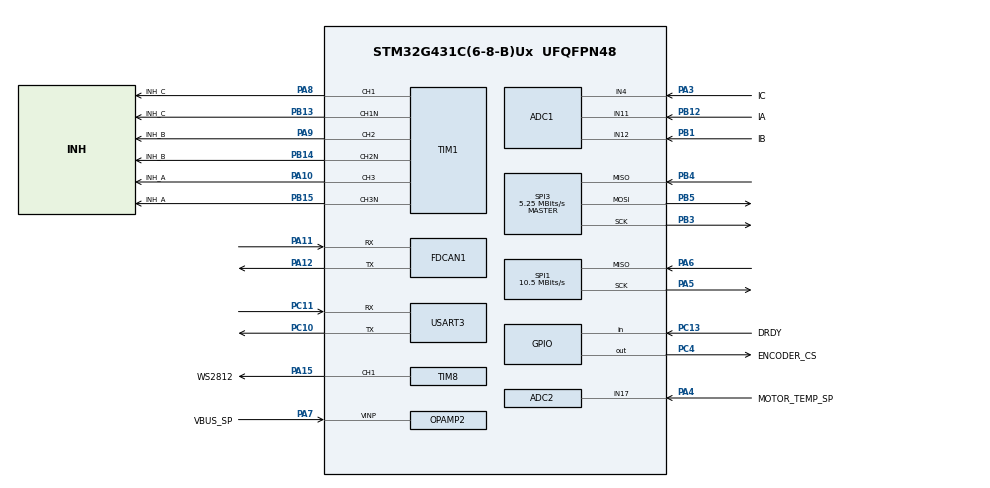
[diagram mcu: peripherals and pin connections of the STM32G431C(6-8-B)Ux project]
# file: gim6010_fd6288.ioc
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ADC1.EnableInjectedConversion=ENABLE
ADC1.EnableRegularConversion=DISABLE
ADC1.ExternalTrigInjecConv=ADC_EXTERNALTRIGINJEC_T1_CC4
ADC1.InjNumberOfConversion=3
ADC1.InjectedChannel-2\#ChannelInjectedConversion=ADC_CHANNEL_11
ADC1.InjectedChannel-3\#ChannelInjectedConversion=ADC_CHANNEL_12
ADC1.InjectedChannel-4\#ChannelInjectedConversion=ADC_CHANNEL_4
ADC1.InjectedOffsetNumber-2\#ChannelInjectedConversion=ADC_OFFSET_NONE
ADC1.InjectedOffsetNumber-3\#ChannelInjectedConversion=ADC_OFFSET_NONE
ADC1.InjectedOffsetNumber-4\#ChannelInjectedConversion=ADC_OFFSET_NONE
ADC1.InjectedRank-2\#ChannelInjectedConversion=1
ADC1.InjectedRank-3\#ChannelInjectedConversion=2
ADC1.InjectedRank-4\#ChannelInjectedConversion=3
ADC1.InjectedSamplingTime-2\#ChannelInjectedConversion=ADC_SAMPLETIME_12CYCLES_5
ADC1.InjectedSamplingTime-3\#ChannelInjectedConversion=ADC_SAMPLETIME_12CYCLES_5
ADC1.InjectedSamplingTime-4\#ChannelInjectedConversion=ADC_SAMPLETIME_12CYCLES_5
ADC1.Rank1_Channel=ADC_CHANNEL_11
ADC1.Rank2_Channel=ADC_CHANNEL_12
ADC1.Rank3_Channel=ADC_CHANNEL_4
ADC1.master=1
ADC2.ContinuousConvMode=DISABLE
ADC2.DMAContinuousRequests=DISABLE
ADC2.EnableInjectedConversion=ENABLE
ADC2.EnableRegularConversion=DISABLE
ADC2.ExternalTrigInjecConv=ADC_EXTERNALTRIGINJEC_T1_CC4
ADC2.InjNumberOfConversion=2
ADC2.InjectedChannel-5\#ChannelInjectedConversion=ADC_CHANNEL_VOPAMP2
ADC2.InjectedChannel-6\#ChannelInjectedConversion=ADC_CHANNEL_17
ADC2.InjectedOffsetNumber-5\#ChannelInjectedConversion=ADC_OFFSET_NONE
ADC2.InjectedOffsetNumber-6\#ChannelInjectedConversion=ADC_OFFSET_NONE
ADC2.InjectedRank-5\#ChannelInjectedConversion=1
ADC2.InjectedRank-6\#ChannelInjectedConversion=2
ADC2.InjectedSamplingTime-5\#ChannelInjectedConversion=ADC_SAMPLETIME_6CYCLES_5
ADC2.InjectedSamplingTime-6\#ChannelInjectedConversion=ADC_SAMPLETIME_6CYCLES_5
ADC2.OversamplingMode=DISABLE
ADC2.Rank1_Channel=ADC_CHANNEL_VOPAMP2
ADC2.Rank2_Channel=ADC_CHANNEL_17
Dma.Request0=TIM8_CH1
Dma.Request1=SPI1_RX
Dma.SPI1_RX.1.Direction=DMA_PERIPH_TO_MEMORY
Dma.SPI1_RX.1.EventEnable=DISABLE
Dma.SPI1_RX.1.Instance=DMA1_Channel1
Dma.SPI1_RX.1.MemDataAlignment=DMA_MDATAALIGN_BYTE
Dma.SPI1_RX.1.MemInc=DMA_MINC_ENABLE
Dma.SPI1_RX.1.Mode=DMA_NORMAL
Dma.SPI1_RX.1.PeriphDataAlignment=DMA_PDATAALIGN_BYTE
Dma.SPI1_RX.1.PeriphInc=DMA_PINC_DISABLE
Dma.SPI1_RX.1.Polarity=HAL_DMAMUX_REQ_GEN_RISING
Dma.SPI1_RX.1.Priority=DMA_PRIORITY_VERY_HIGH
Dma.SPI1_RX.1.RequestNumber=1
Dma.SPI1_RX.1.SignalID=NONE
Dma.SPI1_RX.1.SyncEnable=DISABLE
Dma.SPI1_RX.1.SyncPolarity=HAL_DMAMUX_SYNC_NO_EVENT
Dma.SPI1_RX.1.SyncRequestNumber=1
Dma.SPI1_RX.1.SyncSignalID=NONE
Dma.TIM8_CH1.0.Direction=DMA_MEMORY_TO_PERIPH
Dma.TIM8_CH1.0.EventEnable=DISABLE
Dma.TIM8_CH1.0.Instance=DMA2_Channel1
Dma.TIM8_CH1.0.MemDataAlignment=DMA_MDATAALIGN_HALFWORD
Dma.TIM8_CH1.0.MemInc=DMA_MINC_ENABLE
Dma.TIM8_CH1.0.Mode=DMA_CIRCULAR
Dma.TIM8_CH1.0.PeriphDataAlignment=DMA_PDATAALIGN_HALFWORD
Dma.TIM8_CH1.0.PeriphInc=DMA_PINC_DISABLE
Dma.TIM8_CH1.0.Polarity=HAL_DMAMUX_REQ_GEN_RISING
Dma.TIM8_CH1.0.Priority=DMA_PRIORITY_LOW
Dma.TIM8_CH1.0.RequestNumber=1
Dma.TIM8_CH1.0.SignalID=NONE
Dma.TIM8_CH1.0.SyncEnable=DISABLE
Dma.TIM8_CH1.0.SyncPolarity=HAL_DMAMUX_SYNC_NO_EVENT
Dma.TIM8_CH1.0.SyncRequestNumber=1
Dma.TIM8_CH1.0.SyncSignalID=NONE
FDCAN1.AutoRetransmission=DISABLE
FDCAN1.CalculateBaudRateNominal=1000000
FDCAN1.CalculateTimeBitNominal=1000
FDCAN1.CalculateTimeQuantumNominal=35.714285714285715
FDCAN1.DataPrescaler=6
FDCAN1.DataSyncJumpWidth=7
FDCAN1.DataTimeSeg1=20
FDCAN1.DataTimeSeg2=7
FDCAN1.ExtFiltersNbr=0
FDCAN1.NominalPrescaler=6
FDCAN1.NominalSyncJumpWidth=7
FDCAN1.NominalTimeSeg1=20
FDCAN1.NominalTimeSeg2=7
FDCAN1.StdFiltersNbr=1
Mcu.Family=STM32G4
Mcu.Name=STM32G431C(6-8-B)Ux
Mcu.Package=UFQFPN48
Mcu.UserConstants=PWM_TGRO_TIME,PWM_PERIOD_CLOCKS-10;PWM_DEADTIM_CLOCKS,34;PWM_RCR,0;PWM_PERIOD_CLOCKS,PWM_CLOCK_HZ/2/PWM_FREQ;PWM_FREQ,24000;PWM_CLOCK_HZ,168000000
NVIC.ADC1_2_IRQn=true\:0\:0\:true\:false\:true\:true\:true\:true
NVIC.DMA1_Channel1_IRQn=true\:0\:0\:false\:false\:true\:false\:true\:true
NVIC.DMA2_Channel1_IRQn=true\:0\:0\:false\:false\:true\:false\:true\:true
NVIC.FDCAN1_IT0_IRQn=true\:0\:0\:false\:false\:true\:true\:true\:true
NVIC.PriorityGroup=NVIC_PRIORITYGROUP_4
NVIC.TIM1_UP_TIM16_IRQn=true\:0\:0\:false\:false\:true\:true\:true\:true
NVIC.TIM4_IRQn=true\:0\:0\:false\:false\:true\:true\:true\:true
NVIC.TIM7_IRQn=true\:0\:0\:false\:false\:true\:true\:true\:true
OPAMP2.PowerMode=OPAMP_POWERMODE_HIGHSPEED
PA10.GPIO_Label=INH_A
PA10.Signal=S_TIM1_CH3
PA11.Mode=FDCAN_Activate
PA11.Signal=FDCAN1_RX
PA12.Mode=FDCAN_Activate
PA12.Signal=FDCAN1_TX
PA13.Mode=Serial_Wire
PA13.Signal=SYS_JTMS-SWDIO
PA14.Mode=Serial_Wire
PA14.Signal=SYS_JTCK-SWCLK
PA15.GPIO_Label=WS2812
PA15.Signal=S_TIM8_CH1
PA3.GPIO_Label=IC
PA3.Mode=IN4-Single-Ended
PA3.Signal=ADC1_IN4
PA4.GPIO_Label=MOTOR_TEMP_SP
PA4.Mode=IN17-Single-Ended
PA4.Signal=ADC2_IN17
PA5.GPIO_PuPd=GPIO_PULLDOWN
PA5.GPIO_Speed=GPIO_SPEED_FREQ_VERY_HIGH
PA5.Mode=RX_Only_Simplex_Unidirect_Master
PA5.Signal=SPI1_SCK
PA6.GPIO_Mode=GPIO_MODE_AF_PP
PA6.GPIO_PuPd=GPIO_PULLDOWN
PA6.GPIO_Speed=GPIO_SPEED_FREQ_VERY_HIGH
PA6.Mode=RX_Only_Simplex_Unidirect_Master
PA6.Signal=SPI1_MISO
PA7.GPIO_Label=VBUS_SP
PA7.Mode=Follower_Internally_Connected
PA7.Signal=OPAMP2_VINP
PA8.GPIO_Label=INH_C
PA8.Signal=S_TIM1_CH1
PA9.GPIO_Label=INH_B
PA9.Signal=S_TIM1_CH2
PB1.GPIO_Label=IB
PB1.Mode=IN12-Single-Ended
PB1.Signal=ADC1_IN12
PB12.GPIO_Label=IA
PB12.Mode=IN11-Single-Ended
PB12.Signal=ADC1_IN11
PB13.GPIO_Label=INH_C
PB13.Mode=PWM Generation1 CH1 CH1N
PB13.Signal=TIM1_CH1N
PB14.GPIO_Label=INH_B
PB14.Mode=PWM Generation2 CH2 CH2N
PB14.Signal=TIM1_CH2N
PB15.GPIO_Label=INH_A
PB15.Mode=PWM Generation3 CH3 CH3N
PB15.Signal=TIM1_CH3N
PB3.GPIO_Speed=GPIO_SPEED_FREQ_VERY_HIGH
PB3.Mode=Full_Duplex_Master
PB3.Signal=SPI3_SCK
PB4.GPIO_Speed=GPIO_SPEED_FREQ_VERY_HIGH
PB4.Mode=Full_Duplex_Master
PB4.Signal=SPI3_MISO
PB5.GPIO_Speed=GPIO_SPEED_FREQ_VERY_HIGH
PB5.Mode=Full_Duplex_Master
PB5.Signal=SPI3_MOSI
PC10.Mode=Asynchronous
PC10.Signal=USART3_TX
PC11.Mode=Asynchronous
PC11.Signal=USART3_RX
PC13.GPIO_Label=DRDY
PC13.Signal=GPIO_Input
PC4.GPIO_Label=ENCODER_CS
PC4.GPIO_PuPd=GPIO_PULLUP
PC4.GPIO_Speed=GPIO_SPEED_FREQ_VERY_HIGH
PC4.PinState=GPIO_PIN_SET
PC4.Signal=GPIO_Output
PF0-OSC_IN.Mode=HSE-External-Oscillator
PF0-OSC_IN.Signal=RCC_OSC_IN
PF1-OSC_OUT.Mode=HSE-External-Oscillator
PF1-OSC_OUT.Signal=RCC_OSC_OUT
ProjectManager.HeapSize=0x200
ProjectManager.StackSize=0x400
ProjectManager.TargetToolchain=STM32CubeIDE
RCC.ADC12Freq_Value=168000000
RCC.AHBFreq_Value=168000000
RCC.APB1Freq_Value=168000000
RCC.APB1TimFreq_Value=168000000
RCC.APB2Freq_Value=168000000
RCC.APB2TimFreq_Value=168000000
RCC.CortexFreq_Value=168000000
RCC.EXTERNAL_CLOCK_VALUE=12288000
RCC.EnbaleCSS=true
RCC.HCLKFreq_Value=168000000
RCC.HSE_VALUE=24000000
RCC.HSI48_VALUE=48000000
RCC.HSI_VALUE=16000000
RCC.LPTIM1CLockSelection=RCC_LPTIM1CLKSOURCE_HSI
RCC.LSE_VALUE=32768
RCC.PLLM=RCC_PLLM_DIV2
RCC.PLLN=28
RCC.PLLSourceVirtual=RCC_PLLSOURCE_HSE
RCC.SYSCLKFreq_VALUE=168000000
RCC.SYSCLKSource=RCC_SYSCLKSOURCE_PLLCLK
RCC.USBFreq_Value=168000000
RCC.VCOOutputFreq_Value=336000000
SH.S_TIM1_CH1.0=TIM1_CH1,PWM Generation1 CH1 CH1N
SH.S_TIM1_CH2.0=TIM1_CH2,PWM Generation2 CH2 CH2N
SH.S_TIM1_CH3.0=TIM1_CH3,PWM Generation3 CH3 CH3N
SH.S_TIM8_CH1.0=TIM8_CH1,PWM Generation1 CH1
SPI1.BaudRatePrescaler=SPI_BAUDRATEPRESCALER_16
SPI1.CLKPhase=SPI_PHASE_2EDGE
SPI1.CalculateBaudRate=10.5 MBits/s
SPI1.DataSize=SPI_DATASIZE_8BIT
SPI1.Direction=SPI_DIRECTION_2LINES_RXONLY
SPI1.Mode=SPI_MODE_MASTER
SPI1.VirtualType=VM_MASTER
SPI3.BaudRatePrescaler=SPI_BAUDRATEPRESCALER_32
SPI3.CalculateBaudRate=5.25 MBits/s
SPI3.DataSize=SPI_DATASIZE_8BIT
SPI3.Direction=SPI_DIRECTION_2LINES
SPI3.FirstBit=SPI_FIRSTBIT_MSB
SPI3.Mode=SPI_MODE_MASTER
SPI3.NSSPMode=SPI_NSS_PULSE_DISABLE
SPI3.VirtualType=VM_MASTER
STMicroelectronics.X-CUBE-ALGOBUILD.1.4.0.LibraryCcDSPOoLibraryJjDSPOoLibrary=true
TIM1.AutoReloadPreload=TIM_AUTORELOAD_PRELOAD_DISABLE
TIM1.Channel-PWM\ Generation1\ CH1\ CH1N=TIM_CHANNEL_1
TIM1.Channel-PWM\ Generation2\ CH2\ CH2N=TIM_CHANNEL_2
TIM1.Channel-PWM\ Generation3\ CH3\ CH3N=TIM_CHANNEL_3
TIM1.Channel-PWM\ Generation4\ No\ Output=TIM_CHANNEL_4
TIM1.CounterMode=TIM_COUNTERMODE_CENTERALIGNED1
TIM1.DeadTime=PWM_DEADTIM_CLOCKS
TIM1.OCFastMode_PWM-PWM\ Generation1\ CH1\ CH1N=TIM_OCFAST_DISABLE
TIM1.OCFastMode_PWM-PWM\ Generation2\ CH2\ CH2N=TIM_OCFAST_DISABLE
TIM1.OCFastMode_PWM-PWM\ Generation3\ CH3\ CH3N=TIM_OCFAST_DISABLE
TIM1.OCMode_PWM-PWM\ Generation1\ CH1\ CH1N=TIM_OCMODE_PWM1
TIM1.OCMode_PWM-PWM\ Generation2\ CH2\ CH2N=TIM_OCMODE_PWM1
TIM1.OCMode_PWM-PWM\ Generation3\ CH3\ CH3N=TIM_OCMODE_PWM1
TIM1.OCMode_PWM-PWM\ Generation4\ No\ Output=TIM_OCMODE_PWM2
TIM1.OCPolarity_4=TIM_OCPOLARITY_HIGH
TIM1.OffStateIDLEMode=TIM_OSSI_DISABLE
TIM1.OffStateRunMode=TIM_OSSR_DISABLE
TIM1.PeriodNoDither=PWM_PERIOD_CLOCKS
TIM1.PulseNoDither_1=0
TIM1.PulseNoDither_2=0
TIM1.PulseNoDither_3=0
TIM1.PulseNoDither_4=PWM_TGRO_TIME
TIM1.RepetitionCounter=PWM_RCR
TIM1.TIM_MasterOutputTrigger=TIM_TRGO_OC4REF
TIM4.PeriodNoDither=1000-1
TIM4.Prescaler=170-1
TIM7.PeriodNoDither=5000-1
TIM7.Prescaler=170-1
TIM8.AutoReloadPreload=TIM_AUTORELOAD_PRELOAD_ENABLE
TIM8.Channel-PWM\ Generation1\ CH1=TIM_CHANNEL_1
TIM8.PeriodNoDither=60-1
TIM8.Prescaler=4-1
USART3.VirtualMode-Asynchronous=VM_ASYNC
VP_ADC2_OPAMP_INTERNAL2.Mode=IN-OPAMP2
VP_STMicroelectronics.X-CUBE-ALGOBUILD_VS_DSPOoLibraryJjLibrary_1.4.0_1.4.0.Mode=DSPOoLibraryJjLibrary
VP_SYS_VS_DBSignals.Mode=DisableDeadBatterySignals
VP_TIM1_VS_ClockSourceINT.Mode=Internal
VP_TIM1_VS_no_output4.Mode=PWM Generation4 No Output
VP_TIM4_VS_ClockSourceINT.Mode=Internal
VP_TIM7_VS_ClockSourceINT.Mode=Enable_Timer
VP_TIM8_VS_ClockSourceINT.Mode=Internal
board=custom

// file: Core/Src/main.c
/* USER CODE BEGIN Header */
/**
 ******************************************************************************
 * @file           : main.c
 * @brief          : Main program body
 ******************************************************************************
 * @attention
 *
 * Copyright (c) 2025 STMicroelectronics.
 * All rights reserved.
 *
 * This software is licensed under terms that can be found in the LICENSE file
 * in the root directory of this software component.
 * If no LICENSE file comes with this software, it is provided AS-IS.
 *
 ******************************************************************************
 */
/* USER CODE END Header */
#include "main.h"
#include "adc.h"
#include "dma.h"
#include "fdcan.h"
#include "opamp.h"
#include "spi.h"
#include "tim.h"
#include "usart.h"
#include "gpio.h"

/* USER CODE BEGIN Includes */
#include "motor.h"
#include "ads1120.h"
#include <math.h>
#include <stdint.h>
/* USER CODE END Includes */

void SystemClock_Config(void);

int main(void)
{

    /* MCU Configuration--------------------------------------------------------*/

    /* Reset of all peripherals, Initializes the Flash interface and the Systick. */
    HAL_Init();

    /* Configure the system clock */
    SystemClock_Config();

    /* Initialize all configured peripherals */
    MX_GPIO_Init();
    MX_DMA_Init();
    MX_FDCAN1_Init();
    MX_TIM1_Init();
    MX_SPI1_Init();
    MX_SPI3_Init();
    MX_USART3_UART_Init();
    MX_ADC1_Init();
    MX_ADC2_Init();
    MX_OPAMP2_Init();
    MX_TIM4_Init();
    MX_TIM7_Init();
    MX_TIM8_Init();
    /* USER CODE BEGIN 2 */
    ADS1220Init();
    // MotorInit();
    /* USER CODE END 2 */

    /* Infinite loop */
    /* USER CODE BEGIN WHILE */
    static float angle;
    while (1) {
        angle = Hall_calc_angle();
        /* USER CODE END WHILE */

    }
}

void SystemClock_Config(void)
{
    LL_FLASH_SetLatency(LL_FLASH_LATENCY_4);
    while (LL_FLASH_GetLatency() != LL_FLASH_LATENCY_4) {
    }
    LL_PWR_EnableRange1BoostMode();
    LL_RCC_HSE_Enable();
    /* Wait till HSE is ready */
    while (LL_RCC_HSE_IsReady() != 1) {
    }

    LL_RCC_HSE_EnableCSS();
    LL_RCC_PLL_ConfigDomain_SYS(LL_RCC_PLLSOURCE_HSE, LL_RCC_PLLM_DIV_2, 28, LL_RCC_PLLR_DIV_2);
    LL_RCC_PLL_EnableDomain_SYS();
    LL_RCC_PLL_Enable();
    /* Wait till PLL is ready */
    while (LL_RCC_PLL_IsReady() != 1) {
    }

    LL_RCC_SetSysClkSource(LL_RCC_SYS_CLKSOURCE_PLL);
    LL_RCC_SetAHBPrescaler(LL_RCC_SYSCLK_DIV_2);
    /* Wait till System clock is ready */
    while (LL_RCC_GetSysClkSource() != LL_RCC_SYS_CLKSOURCE_STATUS_PLL) {
    }

    /* Insure 1us transition state at intermediate medium speed clock*/
    for (__IO uint32_t i = (170 >> 1); i != 0; i--);

    /* Set AHB prescaler*/
    LL_RCC_SetAHBPrescaler(LL_RCC_SYSCLK_DIV_1);
    LL_RCC_SetAPB1Prescaler(LL_RCC_APB1_DIV_1);
    LL_RCC_SetAPB2Prescaler(LL_RCC_APB2_DIV_1);
    LL_SetSystemCoreClock(168000000);

    /* Update the time base */
    if (HAL_InitTick(TICK_INT_PRIORITY) != HAL_OK) {
        Error_Handler();
    }
}

void Error_Handler(void)
{
    __disable_irq();
    while (1) {
    }
}
